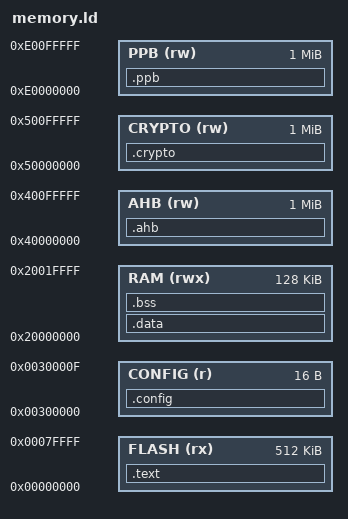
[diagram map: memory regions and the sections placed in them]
/*
 * Copyright (C) 2023 xent
 * Project is distributed under the terms of the GNU General Public License v3.0
 */

ENTRY(RESET_ISR)
EXTERN(vectorTable)

MEMORY
{
  FLASH (rx)  : ORIGIN = 0x00000000, LENGTH = 512K
  RAM (rwx)   : ORIGIN = 0x20000000, LENGTH = 128K

  CONFIG (r)  : ORIGIN = 0x00300000, LENGTH = 16
  AHB (rw)    : ORIGIN = 0x40000000, LENGTH = 1M
  CRYPTO (rw) : ORIGIN = 0x50000000, LENGTH = 1M
  PPB (rw)    : ORIGIN = 0xE0000000, LENGTH = 1M
}

SECTIONS
{
  .text : ALIGN(4)
  {
    _stext = .;

    *(.vectors)
    *(.text)
    *(.text*)
    *(.rodata)
    *(.rodata*)

    _etext = .;

    . = ALIGN(4);
    _sidata = .;
  } >FLASH =0xFF

  .data : AT(_sidata) ALIGN(4)
  {
    _sdata = .;

    *(.data)
    *(.data*)

    _edata = .;
  } >RAM

  .bss : ALIGN(4)
  {
    _sbss = .;

    *(.bss)
    *(.bss*)
    *(COMMON)

    _ebss = .;

    . = ALIGN(4);
    heapStart = .;
  } >RAM

  .config :
  {
    CONFIG_DOMAIN = .;
  } >CONFIG

  .ahb :
  {
    AHB_APB_DOMAIN = .;
  } >AHB

  .crypto :
  {
    CRYPTO_DOMAIN = .;
  } >CRYPTO

  .ppb :
  {
    PPB_DOMAIN = .;
  } >PPB

  /DISCARD/ :
  {
    *(.init)
    *(.fini)

    *(.ARM.exidx*)
    *(.gnu.linkonce.armexidx.*)

    *(.ARM.extab*)
    *(.gnu.linkonce.armextab.*)
  }

  PROVIDE(end = heapStart);
  PROVIDE(_stack = ORIGIN(RAM) + LENGTH(RAM));
}
